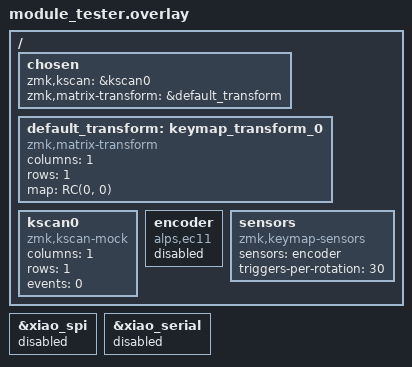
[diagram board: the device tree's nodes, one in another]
#include <dt-bindings/zmk/matrix_transform.h>

/ {
    chosen {
        zmk,kscan = &kscan0;
        zmk,matrix-transform = &default_transform;
    };

    default_transform: keymap_transform_0 {
        compatible = "zmk,matrix-transform";
        columns = <1>;
        rows = <1>;
        map = <RC(0, 0)>;
    };

    kscan0: kscan0 {
        compatible = "zmk,kscan-mock";
        columns = <1>;
        rows = <1>;
        events = <0>;
    };

    encoder: encoder {
        compatible = "alps,ec11";
        status = "disabled";
    };

    sensors: sensors {
        compatible = "zmk,keymap-sensors";
        sensors = <&encoder>;
        triggers-per-rotation = <30>;
    };
};

&xiao_spi {
    status = "disabled";
};

&xiao_serial {
    status = "disabled";
};
